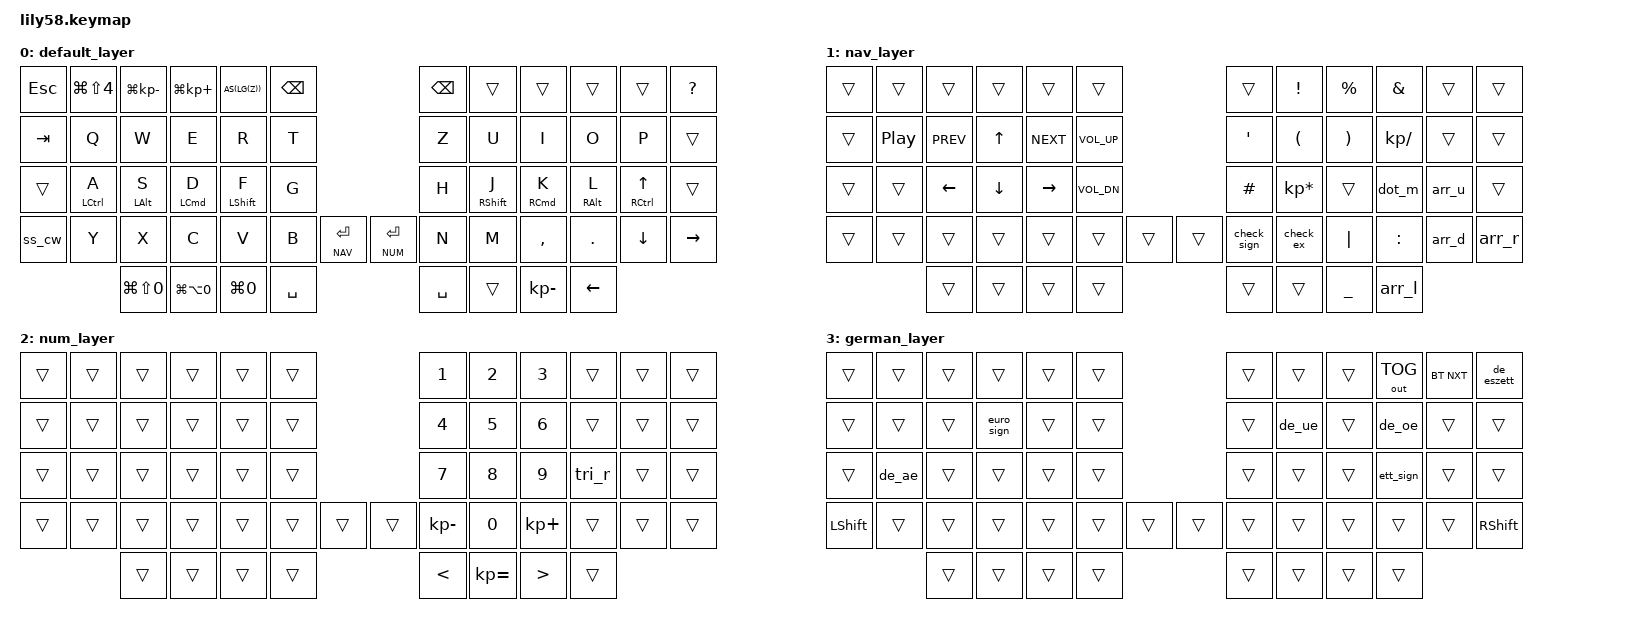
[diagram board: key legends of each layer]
/*
 * Copyright (c) 2020 The ZMK Contributors
 *
 * SPDX-License-Identifier: MIT
 */

#include <behaviors.dtsi>
#include <dt-bindings/zmk/keys.h>
#include <dt-bindings/zmk/bt.h>
#include <dt-bindings/zmk/outputs.h>

#define HOST_OS 2
#include "../zmk-nodefree-config/helper.h"
#include "../zmk-nodefree-config/keypos_def/keypos_58keys.h"
#include "../zmk-nodefree-config/international_chars/german.dtsi"

/* layer and key shortcuts */

#define ___ &trans

#define DEF 0  // layer shortcuts, must match order in which they are defined below
#define NAV 1
#define NUM 2
#define GER 3

/* custom behaviors */

// homerow mods
ZMK_BEHAVIOR(hrm, hold_tap,
    flavor = "balanced";
    tapping-term-ms = <200>;
    quick-tap-ms = <125>;
    global-quick-tap;
    bindings = <&kp>, <&kp>;
)

 // tap: sticky shift | double tap: capsword
 ZMK_BEHAVIOR(ss_cw, tap_dance,
    tapping-term-ms = <200>;
    bindings = <&sk LSHFT>, <&caps_word>;
)

#define AS(keycode) &as LS(keycode) keycode     // Define Display of Autoshift Macro

// Autoshift Macro
ZMK_BEHAVIOR(as, hold_tap,
            flavor = "tap-preferred";
            tapping-term-ms = <150>;
            bindings = <&kp>, <&kp>;
)

// tap: backspace | shift + tap: delete | hold: num layer
// ZMK_BEHAVIOR(bs_del_num, mod_morph,
//    bindings = <&lt NUM BSPC>, <&kp DEL>;
//    mods = <(MOD_LSFT|MOD_RSFT)>;
// )

// replace a/o/u/s with German umlauts when NAV and NUM are held jointly
   ZMK_CONDITIONAL_LAYER(NAV NUM, GER)

// combos - defined in german.dtsi
 #undef COMBO_TERM
 #define COMBO_TERM 40  // timeout of 40ms (default is 30ms if omitted)
 ZMK_COMBO(combo_cut,    &kp LG(X),  LB4 LB5, ALL)  // CMD + X, active on all layers
 ZMK_COMBO(combo_copy,   &kp LG(C),  LB3 LB4, ALL)  // CMD + C, active on all layers
 ZMK_COMBO(combo_paste,  &kp LG(V),  LB2 LB3, ALL)  // CMD + V, active on all layers
 ZMK_COMBO(combo_pastefront,  &kp LG(F),  LL0 LL1, ALL)  // CMD + V, active on all layers
 ZMK_COMBO(combo_pasteback,  &kp LG(B),  LB1 LB2, ALL)  // CMD + V, active on all layers
 
 ZMK_COMBO(combo_northeast,  &arr_notheast,  RL4 RH3, NAV)  // arrow top left, active on nav_layer
 ZMK_COMBO(combo_norhtwest,  &arr_northwest,  RL4 RB6, NAV)  // arrow top right, active on nav_layer
 ZMK_COMBO(combo_southeast,  &arr_southeast,  RB5 RH3, NAV)  // arrow bottom left, active on nav_layer
 ZMK_COMBO(combo_southwest,  &arr_southwest,  RB5 RB6, NAV)  // arrow bottom right, active on nav_layer

 // BT Clear requires two corner keys pressed simultaneously on German layer (NAV+NUM held)
 ZMK_COMBO(combo_bt_clr,  &bt BT_CLR,  LT0 LB0, GER)  // BT Clear, only on German layer (top-left + bottom-left)

/* keymap */

ZMK_LAYER(default_layer,
//  ╭─────────────┬─────────────┬─────────────┬─────────────┬─────────────┬─────────────╮                              ╭─────────────┬─────────────┬─────────────┬─────────────┬─────────────┬─────────────╮
        &kp ESC   &kp LG(LS(NUMBER_4)) &kp LG(KP_MINUS) &kp LG(KP_PLUS) AS(LG(Z)) &kp BACKSPACE                         &kp BACKSPACE      ___           ___           ___           ___       &kp QUESTION
//  ├─────────────┼─────────────┼─────────────┼─────────────┼─────────────┼─────────────┤                              ├─────────────┼─────────────┼─────────────┼─────────────┼─────────────┼─────────────┤
        &kp TAB        &kp Q         &kp W         &kp E         &kp R         &kp T                                        &kp Z         &kp U         &kp I         &kp O         &kp P          ___
//  ├─────────────┼─────────────┼─────────────┼─────────────┼─────────────┼─────────────┤                              ├─────────────┼─────────────┼─────────────┼─────────────┼─────────────┼─────────────┤
          ___      &hrm LCTRL A   &hrm LALT S   &hrm LCMD D  &hrm LSHFT F      &kp G                                        &kp H     &hrm RSHFT J   &hrm RCMD K   &hrm RALT L &hrm RCTRL UP_ARROW    ___
//  ├─────────────┼─────────────┼─────────────┼─────────────┼─────────────┼─────────────┼─────────────╮  ╭─────────────┼─────────────┼─────────────┼─────────────┼─────────────┼─────────────┼─────────────┤
         &ss_cw        &kp Y         &kp X         &kp C         &kp V         &kp B     &lt NAV ENTER    &lt NUM ENTER     &kp N         &kp M      &kp COMMA       &kp DOT  &kp DOWN_ARROW &kp RIGHT_ARROW
//  ╰─────────────┴─────────────┼─────────────┼─────────────┼─────────────┼─────────────╯                              ╰─────────────┼─────────────┼─────────────┼─────────────┼─────────────┴─────────────╯
                &kp LG(LS(NUMBER_0)) &kp LG(LA(NUMBER_0)) &kp LG(NUMBER_0)   &kp SPACE                                    &kp SPACE        ___      &kp KP_MINUS  &kp LEFT_ARROW
//                              ╰─────────────┴─────────────┴─────────────┴─────────────┴─────────────╯  ╰─────────────┴─────────────┴─────────────┴─────────────┴─────────────╯
)

ZMK_LAYER(nav_layer,
//  ╭─────────────┬─────────────┬─────────────┬─────────────┬─────────────┬─────────────╮                              ╭─────────────┬─────────────┬─────────────┬─────────────┬─────────────┬─────────────╮
         ___            ___           ___           ___           ___           ___                                          ___         &kp EXCL     &kp PRCNT     &kp AMPS         ___           ___
//  ├─────────────┼─────────────┼─────────────┼─────────────┼─────────────┼─────────────┤                              ├─────────────┼─────────────┼─────────────┼─────────────┼─────────────┼─────────────┤
         ___         &kp C_PP     &kp C_PREV   &kp UP_ARROW   &kp C_NEXT    &kp C_VOL_UP                                   &kp SQT       &kp LPAR     &kp RPAR      &kp KP_SLASH     ___           ___
//  ├─────────────┼─────────────┼─────────────┼─────────────┼─────────────┼─────────────┤                              ├─────────────┼─────────────┼─────────────┼─────────────┼─────────────┼─────────────┤
         ___            ___    &kp LEFT_ARROW &kp DOWN_ARROW &kp RIGHT_ARROW &kp C_VOL_DN                                  &kp HASH  &kp KP_MULTIPLY     ___          &dot_m        &arr_u         ___
//  ├─────────────┼─────────────┼─────────────┼─────────────┼─────────────┼─────────────┼─────────────╮  ╭─────────────┼─────────────┼─────────────┼─────────────┼─────────────┼─────────────┼─────────────┤
         ___            ___           ___           ___           ___           ___           ___              ___       &check_sign    &check_ex     &kp PIPE      &kp COLON       &arr_d        &arr_r
//  ╰─────────────┴─────────────┼─────────────┼─────────────┼─────────────┼─────────────╯                              ╰─────────────┼─────────────┼─────────────┼─────────────┼─────────────┴─────────────╯
                                      ___           ___           ___           ___                                         ___            ___      &kp UNDERSCORE   &arr_l
//                              ╰─────────────┴─────────────┴─────────────┴─────────────┴─────────────╯  ╰─────────────┴─────────────┴─────────────┴─────────────┴─────────────╯
)

ZMK_LAYER(num_layer,
//  ╭─────────────┬─────────────┬─────────────┬─────────────┬─────────────┬─────────────╮                              ╭─────────────┬─────────────┬─────────────┬─────────────┬─────────────┬─────────────╮
          ___           ___           ___           ___           ___           ___                                     &kp NUMBER_1  &kp NUMBER_2  &kp NUMBER_3       ___           ___           ___
//  ├─────────────┼─────────────┼─────────────┼─────────────┼─────────────┼─────────────┤                              ├─────────────┼─────────────┼─────────────┼─────────────┼─────────────┼─────────────┤
          ___           ___           ___           ___           ___           ___                                     &kp NUMBER_4  &kp NUMBER_5  &kp NUMBER_6       ___           ___           ___
//  ├─────────────┼─────────────┼─────────────┼─────────────┼─────────────┼─────────────┤                              ├─────────────┼─────────────┼─────────────┼─────────────┼─────────────┼─────────────┤
          ___           ___           ___           ___           ___           ___                                     &kp NUMBER_7  &kp NUMBER_8  &kp NUMBER_9      &tri_r         ___           ___
//  ├─────────────┼─────────────┼─────────────┼─────────────┼─────────────┼─────────────┼─────────────╮  ╭─────────────┼─────────────┼─────────────┼─────────────┼─────────────┼─────────────┼─────────────┤
          ___           ___           ___           ___           ___           ___           ___              ___      &kp KP_MINUS  &kp NUMBER_0  &kp KP_PLUS        ___           ___           ___
//  ╰─────────────┴─────────────┼─────────────┼─────────────┼─────────────┼─────────────╯                              ╰─────────────┼─────────────┼─────────────┼─────────────┼─────────────┴─────────────╯
                                      ___           ___           ___           ___                                        &kp LT     &kp KP_EQUAL     &kp GT          ___
//                              ╰─────────────┴─────────────┴─────────────┴─────────────┴─────────────╯  ╰─────────────┴─────────────┴─────────────┴─────────────┴─────────────╯
)

ZMK_LAYER(german_layer,
//  ╭─────────────┬─────────────┬─────────────┬─────────────┬─────────────┬─────────────╮                              ╭─────────────┬─────────────┬─────────────┬─────────────┬─────────────┬─────────────╮
          ___           ___           ___           ___           ___           ___                                          ___           ___           ___     &out OUT_TOG   &bt BT_NXT    &de_eszett
//  ├─────────────┼─────────────┼─────────────┼─────────────┼─────────────┼─────────────┤                              ├─────────────┼─────────────┼─────────────┼─────────────┼─────────────┼─────────────┤
          ___           ___           ___       &euro_sign        ___           ___                                          ___          &de_ue         ___         &de_oe          ___           ___
//  ├─────────────┼─────────────┼─────────────┼─────────────┼─────────────┼─────────────┤                              ├─────────────┼─────────────┼─────────────┼─────────────┼─────────────┼─────────────┤
          ___          &de_ae         ___           ___           ___           ___                                          ___           ___           ___        &ett_sign        ___           ___
//  ├─────────────┼─────────────┼─────────────┼─────────────┼─────────────┼─────────────┼─────────────╮  ╭─────────────┼─────────────┼─────────────┼─────────────┼─────────────┼─────────────┼─────────────┤
      &kp LSHIFT        ___           ___           ___           ___           ___           ___              ___           ___           ___           ___           ___           ___       &kp RSHIFT
//  ╰─────────────┴─────────────┼─────────────┼─────────────┼─────────────┼─────────────╯                              ╰─────────────┼─────────────┼─────────────┼─────────────┼─────────────┴─────────────╯
                                      ___           ___           ___           ___                                          ___           ___           ___           ___
//                              ╰─────────────┴─────────────┴─────────────┴─────────────┴─────────────╯  ╰─────────────┴─────────────┴─────────────┴─────────────┴─────────────╯
)
